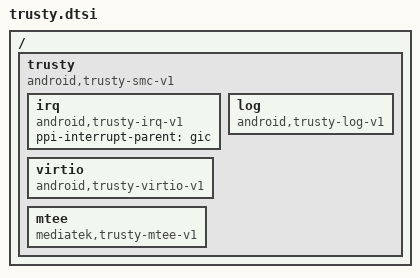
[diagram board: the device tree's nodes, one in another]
/*
 * Copyright (C) 2016 MediaTek Inc.
 *
 * This program is free software; you can redistribute it and/or modify
 * it under the terms of the GNU General Public License version 2 as
 * published by the Free Software Foundation.
 *
 * This program is distributed in the hope that it will be useful,
 * but WITHOUT ANY WARRANTY; without even the implied warranty of
 * MERCHANTABILITY or FITNESS FOR A PARTICULAR PURPOSE.
 * See http://www.gnu.org/licenses/gpl-2.0.html for more details.
 */

/ {
	trusty {
		compatible = "android,trusty-smc-v1";
		ranges;
		#address-cells = <2>;
		#size-cells = <2>;

		irq {
			compatible = "android,trusty-irq-v1";
			ppi-interrupt-parent = <&gic>;
		};

		log {
			compatible = "android,trusty-log-v1";
		};

		virtio {
			compatible = "android,trusty-virtio-v1";
		};

		mtee {
			compatible = "mediatek,trusty-mtee-v1";
		};

	};
};
